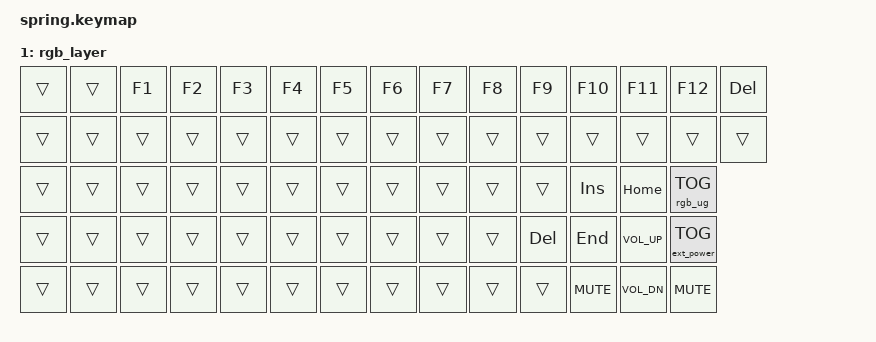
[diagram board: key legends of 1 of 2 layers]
/*
 * Copyright (c) 2021 Nick Winans
 *
 * SPDX-License-Identifier: MIT
 */

#include <behaviors.dtsi>
#include <dt-bindings/zmk/keys.h>
#include <dt-bindings/zmk/bt.h>
#include <dt-bindings/zmk/rgb.h>
#include <dt-bindings/zmk/ext_power.h>

/ {
	keymap {
		compatible = "zmk,keymap";
		
		default_layer {
		// ------------------------------------------------------------------------------------------
		//     | ESC  || `  | 1  | 2  | 3  | 4  | 5  |  6  |-----|  7  |  8  |  9  |  0  |  -  |  =  |   BKSP   |
		//    | PGUP || TAB |  Q  |  W  |  E  |  R  |  T  |---|  Y  |  U  |  I  |  O  |  P  |  [  |  ]  |   "|"  |
		//   | PGDN ||  CLCK |  A  |  S  |  D  |  F  |  G  |---|  H  |  J  |  K  |  L  |  ;  |  '  |     ENTER    |
		//          | LSHIFT  |  Z  |  X  |  C  |  V  |  B  |-|  B  |  N  |  M  |  ,  |  .  |  /  |  UP  | RSHIFT  |
		//         | CTL | WIN |-----| ALT |    SPACE    |----|     SPACE     | MO(1) |---| LEFT | DOWN | RIGHT |
		// ------------------------------------------------------------------------------------------
			bindings = <
			// |----0----|----1----|----2---|---3--|-----4----|----5----|---6--|---7--|---8--|----9----|---10--|---11---|----12---|----13---|---14---|
				&kp ESC   &kp GRAVE &kp N1   &kp N2 &kp N3     &kp N4    &kp N5 &kp N6 &kp N7 &kp N8    &kp N9  &kp N0   &kp MINUS &kp EQUAL &kp BSPC
				&kp PG_UP &kp TAB   &kp Q    &kp W  &kp E      &kp R     &kp T  &kp Y  &kp U  &kp I     &kp O   &kp P    &kp LBKT  &kp RBKT  &kp BSLH
				&kp PG_DN &kp CLCK  &kp A    &kp S  &kp D      &kp F     &kp G  &kp H  &kp J  &kp K     &kp L   &kp SEMI &kp SQT   &kp RET
				&kp LSHFT &kp Z     &kp X    &kp C  &kp V      &kp B     &kp B  &kp N  &kp M  &kp COMMA &kp DOT &kp FSLH &kp UP    &kp RSHFT
				&kp LCTRL &kp LGUI  &kp LALT        &kp SPACE  &kp SPACE                      &mo 1             &kp LEFT &kp DOWN  &kp RIGHT
			>;
		};

		rgb_layer {
		// ------------------------------------------------------------------------------------------
		//     |      ||    | F1 | F2 | F3 | F4 | F5 |  F6 |-----|  F7 |  F8 |  F9 | F10 | F11 | F12 |    RESET    |
		//    |      ||     |     |     |     |     |     |---|     |     |     |     |     |     | SCROLL |       |
		//   |      ||       |     |     |     |     |     |---|     |     |     |     | INS | HOME  |              |
		//          |         |     |     |     |     |     |-|     |     |     |     | DEL |  END  |       |        |
		//         |     |     |-----|     |             |----|               |       |---|      |      |       |
		// ------------------------------------------------------------------------------------------
			bindings = <
			// |---0---|---1---|---2---|---3--|---4---|---5---|---6---|---7---|---8---|---9---|---10--|---11---|---12---|---13---|---14---|
				&trans  &trans  &kp F1  &kp F2  &kp F3  &kp F4  &kp F5  &kp F6  &kp F7  &kp F8  &kp F9  &kp F10    &kp F11      &kp F12  &kp DEL
				&trans  &trans  &trans  &trans  &trans  &trans  &trans  &trans  &trans  &trans  &trans  &trans     &trans       &trans   &trans
				&trans  &trans  &trans  &trans  &trans  &trans  &trans  &trans  &trans  &trans  &trans  &kp INS    &kp HOME     &rgb_ug RGB_TOG
				&trans  &trans  &trans  &trans  &trans  &trans  &trans  &trans  &trans  &trans  &kp DEL &kp END    &kp C_VOL_UP &ext_power EP_TOG   
				&trans  &trans  &trans  &trans  &trans  &trans  &trans  &trans  &trans  &trans  &trans  &kp C_MUTE &kp C_VOL_DN &kp C_MUTE   
			>;
		};
	};

};

